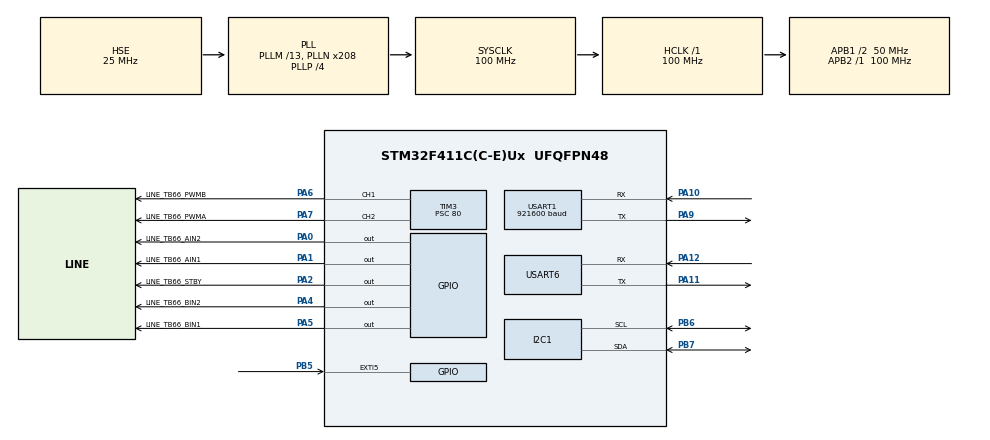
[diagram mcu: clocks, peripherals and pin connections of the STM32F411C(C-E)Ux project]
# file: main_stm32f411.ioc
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FREERTOS.HEAP_NUMBER=3
FREERTOS.Tasks01=defaultTask,0,128,StartDefaultTask,Default,NULL,Dynamic,NULL,NULL
FREERTOS.configMAX_PRIORITIES=32
FREERTOS.configTIMER_TASK_STACK_DEPTH=1024
FREERTOS.configUSE_TIMERS=1
I2C1.I2C_Mode=I2C_Fast
Mcu.Family=STM32F4
Mcu.Name=STM32F411C(C-E)Ux
Mcu.Package=UFQFPN48
NVIC.EXTI9_5_IRQn=true\:10\:0\:true\:false\:true\:false\:true\:true
NVIC.PriorityGroup=NVIC_PRIORITYGROUP_4
NVIC.TIM1_TRG_COM_TIM11_IRQn=true\:0\:0\:false\:false\:true\:false\:false\:true
NVIC.TimeBase=TIM1_TRG_COM_TIM11_IRQn
NVIC.TimeBaseIP=TIM11
NVIC.USART1_IRQn=true\:9\:0\:true\:false\:true\:false\:true\:true
NVIC.USART6_IRQn=true\:10\:0\:true\:false\:true\:false\:true\:true
PA0-WKUP.GPIO_Label=LINE_TB66_AIN2
PA0-WKUP.Signal=GPIO_Output
PA1.GPIO_Label=LINE_TB66_AIN1
PA1.Signal=GPIO_Output
PA10.Mode=Asynchronous
PA10.Signal=USART1_RX
PA11.Mode=Asynchronous
PA11.Signal=USART6_TX
PA12.Mode=Asynchronous
PA12.Signal=USART6_RX
PA13.Mode=Trace_Asynchronous_SW
PA13.Signal=SYS_JTMS-SWDIO
PA14.Mode=Trace_Asynchronous_SW
PA14.Signal=SYS_JTCK-SWCLK
PA2.GPIO_Label=LINE_TB66_STBY
PA2.Signal=GPIO_Output
PA4.GPIO_Label=LINE_TB66_BIN2
PA4.Signal=GPIO_Output
PA5.GPIO_Label=LINE_TB66_BIN1
PA5.Signal=GPIO_Output
PA6.GPIO_Label=LINE_TB66_PWMB
PA6.Signal=S_TIM3_CH1
PA7.GPIO_Label=LINE_TB66_PWMA
PA7.Signal=S_TIM3_CH2
PA9.Mode=Asynchronous
PA9.Signal=USART1_TX
PB3.Mode=Trace_Asynchronous_SW
PB3.Signal=SYS_JTDO-SWO
PB5.Signal=GPXTI5
PB6.Mode=I2C
PB6.Signal=I2C1_SCL
PB7.Mode=I2C
PB7.Signal=I2C1_SDA
PC14-OSC32_IN.Mode=LSE-External-Oscillator
PC14-OSC32_IN.Signal=RCC_OSC32_IN
PC15-OSC32_OUT.Mode=LSE-External-Oscillator
PC15-OSC32_OUT.Signal=RCC_OSC32_OUT
PH0\ -\ OSC_IN.Mode=HSE-External-Oscillator
PH0\ -\ OSC_IN.Signal=RCC_OSC_IN
PH1\ -\ OSC_OUT.Mode=HSE-External-Oscillator
PH1\ -\ OSC_OUT.Signal=RCC_OSC_OUT
ProjectManager.HeapSize=0xFFFFF
ProjectManager.StackSize=0x400
ProjectManager.TargetToolchain=STM32CubeIDE
RCC.48MHZClocksFreq_Value=100000000
RCC.AHBFreq_Value=100000000
RCC.APB1CLKDivider=RCC_HCLK_DIV2
RCC.APB1Freq_Value=50000000
RCC.APB1TimFreq_Value=100000000
RCC.APB2Freq_Value=100000000
RCC.APB2TimFreq_Value=100000000
RCC.CortexFreq_Value=100000000
RCC.HCLKFreq_Value=100000000
RCC.HSE_VALUE=25000000
RCC.HSI_VALUE=16000000
RCC.PLLM=13
RCC.PLLN=208
RCC.PLLP=RCC_PLLP_DIV4
RCC.PLLSourceVirtual=RCC_PLLSOURCE_HSE
RCC.SYSCLKFreq_VALUE=100000000
RCC.SYSCLKSource=RCC_SYSCLKSOURCE_PLLCLK
RCC.VCOOutputFreq_Value=400000000
SH.S_TIM3_CH1.0=TIM3_CH1,PWM Generation1 CH1
SH.S_TIM3_CH2.0=TIM3_CH2,PWM Generation2 CH2
TIM3.AutoReloadPreload=TIM_AUTORELOAD_PRELOAD_ENABLE
TIM3.Channel-PWM\ Generation1\ CH1=TIM_CHANNEL_1
TIM3.Channel-PWM\ Generation2\ CH2=TIM_CHANNEL_2
TIM3.Period=2000
TIM3.Prescaler=80
USART1.BaudRate=921600
USART1.Mode=MODE_TX
USART1.VirtualMode=VM_ASYNC
USART6.VirtualMode=VM_ASYNC
VP_FREERTOS_VS_CMSIS_V1.Mode=CMSIS_V1
VP_SYS_VS_tim11.Mode=TIM11
VP_TIM3_VS_ClockSourceINT.Mode=Internal
board=custom

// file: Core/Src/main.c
/* USER CODE BEGIN Header */
/**
  ******************************************************************************
  * @file           : main.c
  * @brief          : Main program body
  ******************************************************************************
  * @attention
  *
  * <h2><center>&copy; Copyright (c) 2020 STMicroelectronics.
  * All rights reserved.</center></h2>
  *
  * This software component is licensed by ST under BSD 3-Clause license,
  * the "License"; You may not use this file except in compliance with the
  * License. You may obtain a copy of the License at:
  *                        opensource.org/licenses/BSD-3-Clause
  *
  ******************************************************************************
  */
/* USER CODE END Header */
#include "main.h"
#include "cmsis_os.h"
#include "i2c.h"
#include "tim.h"
#include "usart.h"
#include "gpio.h"

void SystemClock_Config(void);
void MX_FREERTOS_Init(void);

int main(void)
{

  /* MCU Configuration--------------------------------------------------------*/

  /* Reset of all peripherals, Initializes the Flash interface and the Systick. */
  HAL_Init();

  /* Configure the system clock */
  SystemClock_Config();

  /* Initialize all configured peripherals */
  MX_GPIO_Init();
  MX_USART1_UART_Init();
  MX_I2C1_Init();
  MX_TIM3_Init();
  MX_USART6_UART_Init();
  /* USER CODE BEGIN 2 */

  main_cpp();

  /* USER CODE END 2 */

  /* Call init function for freertos objects (in freertos.c) */
  MX_FREERTOS_Init();
  /* Start scheduler */
  osKernelStart();

  /* We should never get here as control is now taken by the scheduler */
  /* Infinite loop */
  while (1)
  {

  }
}

void SystemClock_Config(void)
{
  RCC_OscInitTypeDef RCC_OscInitStruct = {0};
  RCC_ClkInitTypeDef RCC_ClkInitStruct = {0};

  /** Configure the main internal regulator output voltage
  */
  __HAL_RCC_PWR_CLK_ENABLE();
  __HAL_PWR_VOLTAGESCALING_CONFIG(PWR_REGULATOR_VOLTAGE_SCALE1);
  /** Initializes the RCC Oscillators according to the specified parameters
  * in the RCC_OscInitTypeDef structure.
  */
  RCC_OscInitStruct.OscillatorType = RCC_OSCILLATORTYPE_HSE;
  RCC_OscInitStruct.HSEState = RCC_HSE_ON;
  RCC_OscInitStruct.PLL.PLLState = RCC_PLL_ON;
  RCC_OscInitStruct.PLL.PLLSource = RCC_PLLSOURCE_HSE;
  RCC_OscInitStruct.PLL.PLLM = 13;
  RCC_OscInitStruct.PLL.PLLN = 208;
  RCC_OscInitStruct.PLL.PLLP = RCC_PLLP_DIV4;
  RCC_OscInitStruct.PLL.PLLQ = 4;
  if (HAL_RCC_OscConfig(&RCC_OscInitStruct) != HAL_OK)
  {
    Error_Handler();
  }
  /** Initializes the CPU, AHB and APB buses clocks
  */
  RCC_ClkInitStruct.ClockType = RCC_CLOCKTYPE_HCLK|RCC_CLOCKTYPE_SYSCLK
                              |RCC_CLOCKTYPE_PCLK1|RCC_CLOCKTYPE_PCLK2;
  RCC_ClkInitStruct.SYSCLKSource = RCC_SYSCLKSOURCE_PLLCLK;
  RCC_ClkInitStruct.AHBCLKDivider = RCC_SYSCLK_DIV1;
  RCC_ClkInitStruct.APB1CLKDivider = RCC_HCLK_DIV2;
  RCC_ClkInitStruct.APB2CLKDivider = RCC_HCLK_DIV1;

  if (HAL_RCC_ClockConfig(&RCC_ClkInitStruct, FLASH_LATENCY_3) != HAL_OK)
  {
    Error_Handler();
  }
}

 /**
  * @brief  Period elapsed callback in non blocking mode
  * @note   This function is called  when TIM11 interrupt took place, inside
  * HAL_TIM_IRQHandler(). It makes a direct call to HAL_IncTick() to increment
  * a global variable "uwTick" used as application time base.
  * @param  htim : TIM handle
  * @retval None
  */
void HAL_TIM_PeriodElapsedCallback(TIM_HandleTypeDef *htim)
{
  if (htim->Instance == TIM11) {
    HAL_IncTick();
  }
}

void Error_Handler(void)
{
  /* USER CODE BEGIN Error_Handler_Debug */
  /* User can add his own implementation to report the HAL error return state */
	exit(1);
  /* USER CODE END Error_Handler_Debug */
}

/************************ (C) COPYRIGHT STMicroelectronics *****END OF FILE****/

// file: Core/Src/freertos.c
/* USER CODE BEGIN Header */
/**
  ******************************************************************************
  * File Name          : freertos.c
  * Description        : Code for freertos applications
  ******************************************************************************
  * @attention
  *
  * <h2><center>&copy; Copyright (c) 2020 STMicroelectronics.
  * All rights reserved.</center></h2>
  *
  * This software component is licensed by ST under Ultimate Liberty license
  * SLA0044, the "License"; You may not use this file except in compliance with
  * the License. You may obtain a copy of the License at:
  *                             www.st.com/SLA0044
  *
  ******************************************************************************
  */
/* USER CODE END Header */

#include "FreeRTOS.h"
#include "task.h"
#include "main.h"
#include "cmsis_os.h"

osThreadId defaultTaskHandle;

void StartDefaultTask(void const * argument);

void MX_FREERTOS_Init(void); /* (MISRA C 2004 rule 8.1) */

/* GetIdleTaskMemory prototype (linked to static allocation support) */
void vApplicationGetIdleTaskMemory( StaticTask_t **ppxIdleTaskTCBBuffer, StackType_t **ppxIdleTaskStackBuffer, uint32_t *pulIdleTaskStackSize );

/* GetTimerTaskMemory prototype (linked to static allocation support) */
void vApplicationGetTimerTaskMemory( StaticTask_t **ppxTimerTaskTCBBuffer, StackType_t **ppxTimerTaskStackBuffer, uint32_t *pulTimerTaskStackSize );

/* USER CODE BEGIN GET_IDLE_TASK_MEMORY */
static StaticTask_t xIdleTaskTCBBuffer;
static StackType_t xIdleStack[configMINIMAL_STACK_SIZE];

void vApplicationGetIdleTaskMemory( StaticTask_t **ppxIdleTaskTCBBuffer, StackType_t **ppxIdleTaskStackBuffer, uint32_t *pulIdleTaskStackSize )
{
  *ppxIdleTaskTCBBuffer = &xIdleTaskTCBBuffer;
  *ppxIdleTaskStackBuffer = &xIdleStack[0];
  *pulIdleTaskStackSize = configMINIMAL_STACK_SIZE;
  /* place for user code */
}
/* USER CODE END GET_IDLE_TASK_MEMORY */

/* USER CODE BEGIN GET_TIMER_TASK_MEMORY */
static StaticTask_t xTimerTaskTCBBuffer;
static StackType_t xTimerStack[configTIMER_TASK_STACK_DEPTH];

void vApplicationGetTimerTaskMemory( StaticTask_t **ppxTimerTaskTCBBuffer, StackType_t **ppxTimerTaskStackBuffer, uint32_t *pulTimerTaskStackSize )
{
  *ppxTimerTaskTCBBuffer = &xTimerTaskTCBBuffer;
  *ppxTimerTaskStackBuffer = &xTimerStack[0];
  *pulTimerTaskStackSize = configTIMER_TASK_STACK_DEPTH;
  /* place for user code */
}
/* USER CODE END GET_TIMER_TASK_MEMORY */

void MX_FREERTOS_Init(void) {

  /* Create the thread(s) */
  /* definition and creation of defaultTask */
  osThreadDef(defaultTask, StartDefaultTask, osPriorityNormal, 0, 128);
  defaultTaskHandle = osThreadCreate(osThread(defaultTask), NULL);

}

void StartDefaultTask(void const * argument)
{
  for(;;)
  {
    osDelay(1);
  }
}

/************************ (C) COPYRIGHT STMicroelectronics *****END OF FILE****/
